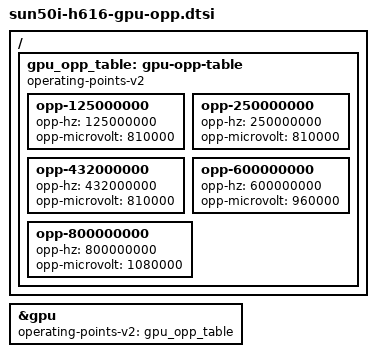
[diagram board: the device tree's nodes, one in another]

/ {
	gpu_opp_table: gpu-opp-table {
		compatible = "operating-points-v2";

		opp-125000000 {
			opp-hz = /bits/ 64 <125000000>;
			opp-microvolt = <810000>;
		};

		opp-250000000 {
			opp-hz = /bits/ 64 <250000000>;
			opp-microvolt = <810000>;
		};

		opp-432000000 {
			opp-hz = /bits/ 64 <432000000>;
			opp-microvolt = <810000>;
		};

		opp-600000000 {
			opp-hz = /bits/ 64 <600000000>;
			opp-microvolt = <960000>;
		};

		opp-800000000 {
			opp-hz = /bits/ 64 <800000000>;
			opp-microvolt = <1080000>;
		};
	};
};

&gpu {
	operating-points-v2 = <&gpu_opp_table>;
};
